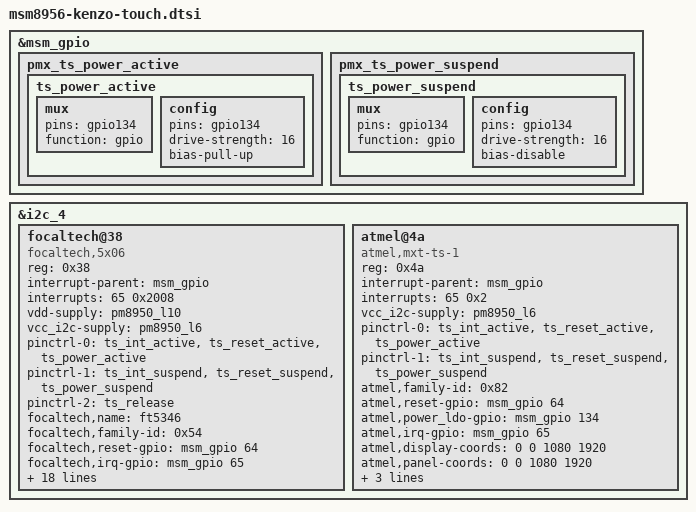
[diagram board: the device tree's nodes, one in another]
/*
 * Touchscreen controllers and pinctrl for Xiaomi Redmi Note 3 (kenzo/kate).
 */

&msm_gpio {
	pmx_ts_power_active {
		ts_power_active: ts_power_active {
			mux {
				pins = "gpio134";
				function = "gpio";
			};

			config {
				pins = "gpio134";
				drive-strength = <16>;
				bias-pull-up;
			};
		};
	};

	pmx_ts_power_suspend {
		ts_power_suspend: ts_power_suspend {
			mux {
				pins = "gpio134";
				function = "gpio";
			};

			config {
				pins = "gpio134";
				drive-strength = <16>;
				bias-disable;
			};
		};
	};
};

/*
 * Phones carry either the FocalTech or the Atmel controller. Both are
 * described; the driver for the absent one fails its probe.
 */
&i2c_4 {
	/delete-node/ synaptics@20;

	focaltech@38 {
		compatible = "focaltech,5x06";
		reg = <0x38>;
		interrupt-parent = <&msm_gpio>;
		interrupts = <65 0x2008>;
		vdd-supply = <&pm8950_l10>;
		vcc_i2c-supply = <&pm8950_l6>;
		pinctrl-names = "pmx_ts_active", "pmx_ts_suspend",
				"pmx_ts_release";
		pinctrl-0 = <&ts_int_active &ts_reset_active &ts_power_active>;
		pinctrl-1 = <&ts_int_suspend &ts_reset_suspend
			     &ts_power_suspend>;
		pinctrl-2 = <&ts_release>;
		focaltech,name = "ft5346";
		focaltech,family-id = <0x54>;
		focaltech,reset-gpio = <&msm_gpio 64 0x0>;
		focaltech,irq-gpio = <&msm_gpio 65 0x2008>;
		focaltech,power-gpio = <&msm_gpio 134 0x0>;
		focaltech,display-coords = <0 0 1080 1920>;
		focaltech,panel-coords = <0 0 1080 2098>;
		focaltech,button-map = <139 102 158>;
		focaltech,fw-name = "ct820_ft_fw.bin";
		focaltech,i2c-pull-up;
		focaltech,group-id = <1>;
		focaltech,hard-reset-delay-ms = <20>;
		focaltech,soft-reset-delay-ms = <30>;
		focaltech,num-max-touches = <10>;
		focaltech,fw-delay-aa-ms = <2>;
		focaltech,fw-delay-55-ms = <2>;
		focaltech,fw-upgrade-id1 = <0x54>;
		focaltech,fw-upgrade-id2 = <0x2c>;
		focaltech,fw-delay-readid-ms = <10>;
		focaltech,fw-delay-era-flsh-ms = <2000>;
		focaltech,fw-auto-cal;
		focaltech,ignore-id-check;
	};

	atmel@4a {
		compatible = "atmel,mxt-ts-1";
		reg = <0x4a>;
		interrupt-parent = <&msm_gpio>;
		interrupts = <65 0x2>;
		vcc_i2c-supply = <&pm8950_l6>;
		pinctrl-names = "pmx_ts_active", "pmx_ts_suspend";
		pinctrl-0 = <&ts_int_active &ts_reset_active &ts_power_active>;
		pinctrl-1 = <&ts_int_suspend &ts_reset_suspend
			     &ts_power_suspend>;
		atmel,family-id = <0x82>;
		atmel,reset-gpio = <&msm_gpio 64 0x0>;
		atmel,power_ldo-gpio = <&msm_gpio 134 0x0>;
		atmel,irq-gpio = <&msm_gpio 65 0x2008>;
		atmel,display-coords = <0 0 1080 1920>;
		atmel,panel-coords = <0 0 1080 1920>;
		atmel,button-map = <158 102 139>;
		atmel,no-force-update;
		atmel,i2c-pull-up;
	};
};
